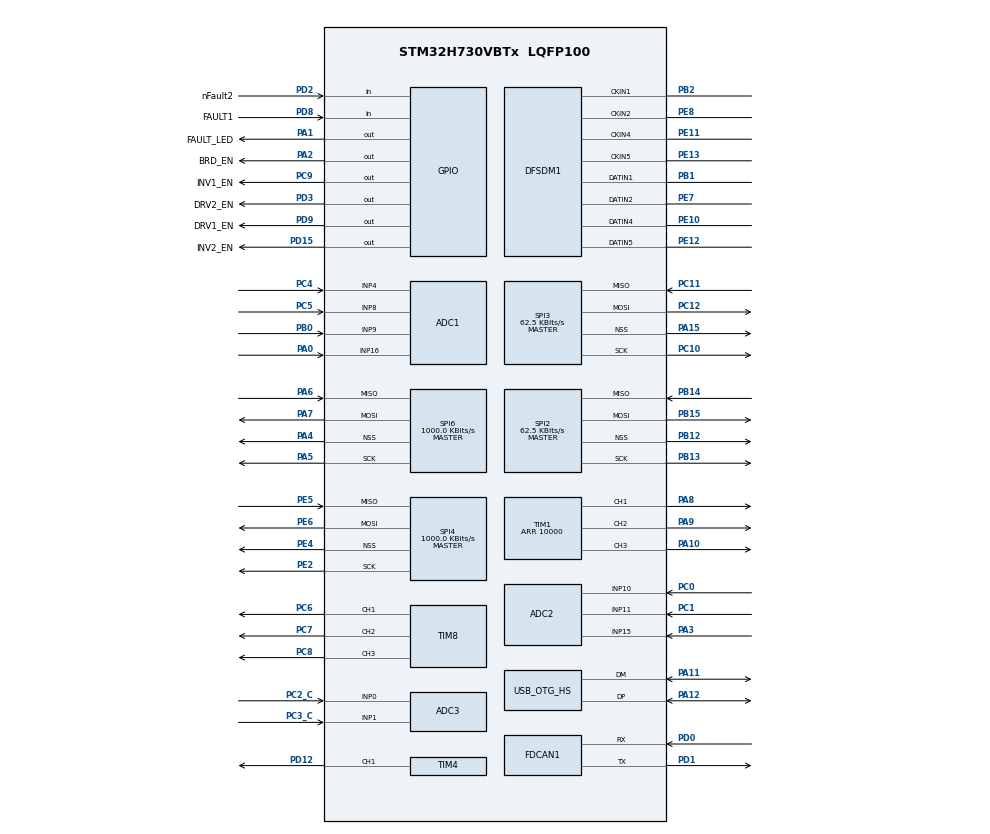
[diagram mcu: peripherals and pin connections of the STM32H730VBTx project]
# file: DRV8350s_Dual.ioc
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ADC1.Channel-10\#ChannelRegularConversion=ADC_CHANNEL_4
ADC1.Channel-11\#ChannelRegularConversion=ADC_CHANNEL_8
ADC1.Channel-12\#ChannelRegularConversion=ADC_CHANNEL_9
ADC1.Channel-13\#ChannelRegularConversion=ADC_CHANNEL_16
ADC1.ClockPrescaler=ADC_CLOCK_ASYNC_DIV6
ADC1.ContinuousConvMode=ENABLE
ADC1.ConversionDataManagement=ADC_CONVERSIONDATA_DR
ADC1.EOCSelection=ADC_EOC_SINGLE_CONV
ADC1.EnableRegularConversion=ENABLE
ADC1.ExternalTrigConv=ADC_SOFTWARE_START
ADC1.NbrOfConversion=4
ADC1.NbrOfConversionFlag=1
ADC1.OffsetNumber-10\#ChannelRegularConversion=ADC_OFFSET_NONE
ADC1.OffsetNumber-11\#ChannelRegularConversion=ADC_OFFSET_NONE
ADC1.OffsetNumber-12\#ChannelRegularConversion=ADC_OFFSET_NONE
ADC1.OffsetNumber-13\#ChannelRegularConversion=ADC_OFFSET_NONE
ADC1.OffsetSignedSaturation-10\#ChannelRegularConversion=DISABLE
ADC1.OffsetSignedSaturation-11\#ChannelRegularConversion=DISABLE
ADC1.OffsetSignedSaturation-12\#ChannelRegularConversion=DISABLE
ADC1.OffsetSignedSaturation-13\#ChannelRegularConversion=DISABLE
ADC1.Overrun=ADC_OVR_DATA_OVERWRITTEN
ADC1.OversamplingMode=ENABLE
ADC1.Rank-10\#ChannelRegularConversion=1
ADC1.Rank-11\#ChannelRegularConversion=2
ADC1.Rank-12\#ChannelRegularConversion=3
ADC1.Rank-13\#ChannelRegularConversion=4
ADC1.Ratio=2
ADC1.RightBitShift=ADC_RIGHTBITSHIFT_NONE
ADC1.SamplingTime-10\#ChannelRegularConversion=ADC_SAMPLETIME_64CYCLES_5
ADC1.SamplingTime-11\#ChannelRegularConversion=ADC_SAMPLETIME_64CYCLES_5
ADC1.SamplingTime-12\#ChannelRegularConversion=ADC_SAMPLETIME_64CYCLES_5
ADC1.SamplingTime-13\#ChannelRegularConversion=ADC_SAMPLETIME_64CYCLES_5
ADC1.master=1
ADC2.Channel-3\#ChannelRegularConversion=ADC_CHANNEL_10
ADC2.Channel-4\#ChannelRegularConversion=ADC_CHANNEL_11
ADC2.Channel-5\#ChannelRegularConversion=ADC_CHANNEL_15
ADC2.ClockPrescaler=ADC_CLOCK_ASYNC_DIV6
ADC2.ContinuousConvMode=DISABLE
ADC2.ConversionDataManagement=ADC_CONVERSIONDATA_DMA_CIRCULAR
ADC2.EOCSelection=ADC_EOC_SINGLE_CONV
ADC2.NbrOfConversion=3
ADC2.NbrOfConversionFlag=1
ADC2.OffsetNumber-3\#ChannelRegularConversion=ADC_OFFSET_NONE
ADC2.OffsetNumber-4\#ChannelRegularConversion=ADC_OFFSET_NONE
ADC2.OffsetNumber-5\#ChannelRegularConversion=ADC_OFFSET_NONE
ADC2.OffsetSignedSaturation-3\#ChannelRegularConversion=DISABLE
ADC2.OffsetSignedSaturation-4\#ChannelRegularConversion=DISABLE
ADC2.OffsetSignedSaturation-5\#ChannelRegularConversion=DISABLE
ADC2.Overrun=ADC_OVR_DATA_OVERWRITTEN
ADC2.Rank-3\#ChannelRegularConversion=1
ADC2.Rank-4\#ChannelRegularConversion=2
ADC2.Rank-5\#ChannelRegularConversion=3
ADC2.SamplingTime-3\#ChannelRegularConversion=ADC_SAMPLETIME_8CYCLES_5
ADC2.SamplingTime-4\#ChannelRegularConversion=ADC_SAMPLETIME_8CYCLES_5
ADC2.SamplingTime-5\#ChannelRegularConversion=ADC_SAMPLETIME_8CYCLES_5
ADC3.Channel-4\#ChannelRegularConversion=ADC_CHANNEL_1
ADC3.ClockPrescaler=ADC_CLOCK_ASYNC_DIV6
ADC3.ContinuousConvMode=ENABLE
ADC3.ConversionDataManagement=ADC_CONVERSIONDATA_DR
ADC3.DMAContinuousRequests=DISABLE
ADC3.EOCSelection=ADC_EOC_SINGLE_CONV
ADC3.NbrOfConversion=1
ADC3.NbrOfConversionFlag=1
ADC3.OffsetNumber-4\#ChannelRegularConversion=ADC_OFFSET_NONE
ADC3.OffsetSaturation-4\#ChannelRegularConversion=DISABLE
ADC3.OffsetSign-4\#ChannelRegularConversion=ADC3_OFFSET_SIGN_NEGATIVE
ADC3.OffsetSignedSaturation-4\#ChannelRegularConversion=DISABLE
ADC3.Overrun=ADC_OVR_DATA_OVERWRITTEN
ADC3.OversamplingMode=ENABLE
ADC3.Rank-4\#ChannelRegularConversion=1
ADC3.Ratio=16
ADC3.RightBitShift=ADC_RIGHTBITSHIFT_5
ADC3.SamplingTime-4\#ChannelRegularConversion=ADC3_SAMPLETIME_92CYCLES_5
CORTEX_M7.CPU_ICache=Enabled
DFSDM1.Filter_regChannel_FIL0=DFSDM_CHANNEL_1
DFSDM1.Filter_regChannel_FIL1=DFSDM_CHANNEL_2
DFSDM1.Filter_regChannel_FIL2=DFSDM_CHANNEL_4
DFSDM1.Filter_regChannel_FIL3=DFSDM_CHANNEL_5
DFSDM1.Fosr_FIL0=32
DFSDM1.Fosr_FIL1=32
DFSDM1.Fosr_FIL2=32
DFSDM1.Fosr_FIL3=32
DFSDM1.SincOrder_FIL0=DFSDM_FILTER_SINC3_ORDER
DFSDM1.SincOrder_FIL1=DFSDM_FILTER_SINC3_ORDER
DFSDM1.SincOrder_FIL2=DFSDM_FILTER_SINC3_ORDER
DFSDM1.SincOrder_FIL3=DFSDM_FILTER_SINC3_ORDER
DFSDM1.Type_spi_CH1=DFSDM_CHANNEL_SPI_RISING
Dma.ADC2.0.Direction=DMA_PERIPH_TO_MEMORY
Dma.ADC2.0.EventEnable=DISABLE
Dma.ADC2.0.FIFOMode=DMA_FIFOMODE_DISABLE
Dma.ADC2.0.Instance=DMA1_Stream1
Dma.ADC2.0.MemDataAlignment=DMA_MDATAALIGN_WORD
Dma.ADC2.0.MemInc=DMA_MINC_ENABLE
Dma.ADC2.0.Mode=DMA_CIRCULAR
Dma.ADC2.0.PeriphDataAlignment=DMA_PDATAALIGN_WORD
Dma.ADC2.0.PeriphInc=DMA_PINC_DISABLE
Dma.ADC2.0.Polarity=HAL_DMAMUX_REQ_GEN_RISING
Dma.ADC2.0.Priority=DMA_PRIORITY_MEDIUM
Dma.ADC2.0.RequestNumber=1
Dma.ADC2.0.SignalID=NONE
Dma.ADC2.0.SyncEnable=DISABLE
Dma.ADC2.0.SyncPolarity=HAL_DMAMUX_SYNC_NO_EVENT
Dma.ADC2.0.SyncRequestNumber=1
Dma.ADC2.0.SyncSignalID=NONE
Dma.Request0=ADC2
Mcu.Family=STM32H7
Mcu.Name=STM32H730VBTx
Mcu.Package=LQFP100
NVIC.ADC3_IRQn=true\:0\:0\:false\:false\:true\:true\:true\:true
NVIC.ADC_IRQn=true\:0\:0\:false\:false\:true\:true\:true\:true
NVIC.DMA1_Stream1_IRQn=true\:0\:0\:false\:false\:true\:false\:true\:true
NVIC.OTG_HS_IRQn=true\:0\:0\:false\:false\:true\:false\:true\:true
NVIC.PriorityGroup=NVIC_PRIORITYGROUP_4
NVIC.TIM2_IRQn=true\:0\:0\:false\:false\:true\:true\:true\:true
PA0.Mode=IN16-Single-Ended
PA0.Signal=ADC1_INP16
PA1.GPIO_Label=FAULT_LED
PA1.Signal=GPIO_Output
PA10.Signal=S_TIM1_CH3
PA11.Mode=Device_Only_FS
PA11.Signal=USB_OTG_HS_DM
PA12.Mode=Device_Only_FS
PA12.Signal=USB_OTG_HS_DP
PA13(JTMS/SWDIO).Mode=Serial_Wire
PA13(JTMS/SWDIO).Signal=DEBUG_JTMS-SWDIO
PA14(JTCK/SWCLK).Mode=Serial_Wire
PA14(JTCK/SWCLK).Signal=DEBUG_JTCK-SWCLK
PA15(JTDI).GPIO_PuPd=GPIO_NOPULL
PA15(JTDI).Mode=NSS_Signal_Hard_Output
PA15(JTDI).Signal=SPI3_NSS
PA2.GPIO_Label=BRD_EN
PA2.Signal=GPIO_Output
PA3.Signal=ADCx_INP15
PA4.Mode=NSS_Signal_Hard_Output
PA4.Signal=SPI6_NSS
PA5.Mode=Full_Duplex_Master
PA5.Signal=SPI6_SCK
PA6.GPIO_PuPd=GPIO_NOPULL
PA6.Mode=Full_Duplex_Master
PA6.Signal=SPI6_MISO
PA7.Mode=Full_Duplex_Master
PA7.Signal=SPI6_MOSI
PA8.Signal=S_TIM1_CH1
PA9.Signal=S_TIM1_CH2
PB0.Signal=ADCx_INP9
PB1.Signal=S_DATAIN1DFSDM1
PB12.GPIO_PuPd=GPIO_NOPULL
PB12.Mode=NSS_Signal_Hard_Output
PB12.Signal=SPI2_NSS
PB13.Mode=Full_Duplex_Master
PB13.Signal=SPI2_SCK
PB14.GPIO_PuPd=GPIO_PULLUP
PB14.Mode=Full_Duplex_Master
PB14.Signal=SPI2_MISO
PB15.GPIO_PuPd=GPIO_NOPULL
PB15.Mode=Full_Duplex_Master
PB15.Signal=SPI2_MOSI
PB2.Signal=S_CKIN1DFSDM1
PC0.Signal=ADCx_INP10
PC1.Signal=ADCx_INP11
PC10.Mode=Full_Duplex_Master
PC10.Signal=SPI3_SCK
PC11.GPIO_PuPd=GPIO_PULLUP
PC11.Mode=Full_Duplex_Master
PC11.Signal=SPI3_MISO
PC12.Mode=Full_Duplex_Master
PC12.Signal=SPI3_MOSI
PC2_C.Mode=IN0-Single-Ended
PC2_C.Signal=ADC3_INP0
PC3_C.Mode=IN1-Single-Ended
PC3_C.Signal=ADC3_INP1
PC4.Signal=ADCx_INP4
PC5.Signal=ADCx_INP8
PC6.Signal=S_TIM8_CH1
PC7.Signal=S_TIM8_CH2
PC8.Signal=S_TIM8_CH3
PC9.GPIO_Label=INV1_EN
PC9.Signal=GPIO_Output
PD0.Mode=FDCAN_Activate
PD0.Signal=FDCAN1_RX
PD1.Mode=FDCAN_Activate
PD1.Signal=FDCAN1_TX
PD12.Signal=S_TIM4_CH1
PD15.GPIO_Label=INV2_EN
PD15.Signal=GPIO_Output
PD2.GPIO_Label=nFault2
PD2.Signal=GPIO_Input
PD3.GPIO_Label=DRV2_EN
PD3.Signal=GPIO_Output
PD8.GPIO_Label=FAULT1
PD8.Signal=GPIO_Input
PD9.GPIO_Label=DRV1_EN
PD9.Signal=GPIO_Output
PE10.Signal=S_DATAIN4DFSDM1
PE11.Signal=S_CKIN4DFSDM1
PE12.Signal=S_DATAIN5DFSDM1
PE13.Signal=S_CKIN5DFSDM1
PE2.Mode=Full_Duplex_Master
PE2.Signal=SPI4_SCK
PE4.GPIO_PuPd=GPIO_NOPULL
PE4.Mode=NSS_Signal_Hard_Output
PE4.Signal=SPI4_NSS
PE5.Mode=Full_Duplex_Master
PE5.Signal=SPI4_MISO
PE6.Mode=Full_Duplex_Master
PE6.Signal=SPI4_MOSI
PE7.Signal=S_DATAIN2DFSDM1
PE8.Signal=S_CKIN2DFSDM1
PH0-OSC_IN.Mode=HSE-External-Clock-Source
PH0-OSC_IN.Signal=RCC_OSC_IN
ProjectManager.HeapSize=0x200
ProjectManager.StackSize=0x400
ProjectManager.TargetToolchain=STM32CubeIDE
RCC.ADCCLockSelection=RCC_ADCCLKSOURCE_CLKP
RCC.ADCFreq_Value=4000000
RCC.APB1Freq_Value=137499975
RCC.APB2Freq_Value=137499975
RCC.APB3Freq_Value=137499975
RCC.APB4Freq_Value=137499975
RCC.CKPERSourceSelection=RCC_CLKPSOURCE_CSI
RCC.CortexFreq_Value=549999900
RCC.D1PPRE=RCC_APB3_DIV2
RCC.D2PPRE1=RCC_APB1_DIV2
RCC.D2PPRE2=RCC_APB2_DIV2
RCC.D3PPRE=RCC_APB4_DIV2
RCC.DIVM1=3
RCC.DIVM2=4
RCC.DIVM3=1
RCC.DIVN1=74
RCC.DIVN2=17
RCC.DIVN3=6
RCC.DIVP1=1
RCC.DIVP2=1
RCC.DIVP3=1
RCC.DIVQ1=10
RCC.DIVQ2=1
RCC.DIVQ3=1
RCC.DIVR1=10
RCC.DIVR3=1
RCC.FDCANCLockSelection=RCC_FDCANCLKSOURCE_HSE
RCC.HCLKFreq_Value=274999950
RCC.HPRE=RCC_HCLK_DIV2
RCC.HSE_Timout=1000
RCC.HSE_VALUE=22118400
RCC.HSICalibrationValue=8
RCC.HSIDiv=RCC_PLLSAIDIVR_8
RCC.PLL2FRACN=4699
RCC.PLL3FRACN=0
RCC.PLLFRACN=4903
RCC.PLLSourceVirtual=RCC_PLLSOURCE_HSE
RCC.SPI123CLockSelection=RCC_SPI123CLKSOURCE_CLKP
RCC.SPI6CLockSelection=RCC_SPI6CLKSOURCE_CSI
RCC.SYSCLKFreq_VALUE=549999900
RCC.SYSCLKSource=RCC_SYSCLKSOURCE_PLLCLK
RCC.Spi45ClockSelection=RCC_SPI45CLKSOURCE_CSI
RCC.SupplySource=PWR_LDO_SUPPLY
RCC.USBCLockSelection=RCC_USBCLKSOURCE_HSI48
RCC.USBFreq_Value=48000000
SH.ADCx_INP10.0=ADC2_INP10,IN10-Single-Ended
SH.ADCx_INP11.0=ADC2_INP11,IN11-Single-Ended
SH.ADCx_INP15.0=ADC2_INP15,IN15-Single-Ended
SH.ADCx_INP4.0=ADC1_INP4,IN4-Single-Ended
SH.ADCx_INP8.0=ADC1_INP8,IN8-Single-Ended
SH.ADCx_INP9.0=ADC1_INP9,IN9-Single-Ended
SH.S_CKIN1DFSDM1.0=DFSDM1_CKIN1,PDM_SPI_input_from_ch1_and_external_clock
SH.S_CKIN2DFSDM1.0=DFSDM1_CKIN2,PDM_SPI_input_from_ch2_and_external_clock
SH.S_CKIN4DFSDM1.0=DFSDM1_CKIN4,PDM_SPI_input_from_ch4_and_external_clock
SH.S_CKIN5DFSDM1.0=DFSDM1_CKIN5,PDM_SPI_input_from_ch5_and_external_clock
SH.S_DATAIN1DFSDM1.0=DFSDM1_DATIN1,PDM_SPI_input_from_ch1_and_external_clock
SH.S_DATAIN2DFSDM1.0=DFSDM1_DATIN2,PDM_SPI_input_from_ch2_and_external_clock
SH.S_DATAIN4DFSDM1.0=DFSDM1_DATIN4,PDM_SPI_input_from_ch4_and_external_clock
SH.S_DATAIN5DFSDM1.0=DFSDM1_DATIN5,PDM_SPI_input_from_ch5_and_external_clock
SH.S_TIM1_CH1.0=TIM1_CH1,PWM Generation1 CH1
SH.S_TIM1_CH2.0=TIM1_CH2,PWM Generation2 CH2
SH.S_TIM1_CH3.0=TIM1_CH3,PWM Generation3 CH3
SH.S_TIM4_CH1.0=TIM4_CH1,PWM Generation1 CH1
SH.S_TIM8_CH1.0=TIM8_CH1,PWM Generation1 CH1
SH.S_TIM8_CH2.0=TIM8_CH2,PWM Generation2 CH2
SH.S_TIM8_CH3.0=TIM8_CH3,Output Compare3 CH3
SPI2.BaudRatePrescaler=SPI_BAUDRATEPRESCALER_64
SPI2.CLKPhase=SPI_PHASE_2EDGE
SPI2.CalculateBaudRate=62.5 KBits/s
SPI2.DataSize=SPI_DATASIZE_16BIT
SPI2.Direction=SPI_DIRECTION_2LINES
SPI2.MasterKeepIOState=SPI_MASTER_KEEP_IO_STATE_ENABLE
SPI2.Mode=SPI_MODE_MASTER
SPI2.NSSPMode=SPI_NSS_PULSE_DISABLE
SPI2.NSSPolarity=SPI_NSS_POLARITY_LOW
SPI2.VirtualNSS=VM_NSSHARD
SPI2.VirtualType=VM_MASTER
SPI3.BaudRatePrescaler=SPI_BAUDRATEPRESCALER_64
SPI3.CLKPhase=SPI_PHASE_2EDGE
SPI3.CalculateBaudRate=62.5 KBits/s
SPI3.DataSize=SPI_DATASIZE_16BIT
SPI3.Direction=SPI_DIRECTION_2LINES
SPI3.MasterKeepIOState=SPI_MASTER_KEEP_IO_STATE_ENABLE
SPI3.Mode=SPI_MODE_MASTER
SPI3.NSSPMode=SPI_NSS_PULSE_DISABLE
SPI3.NSSPolarity=SPI_NSS_POLARITY_LOW
SPI3.VirtualNSS=VM_NSSHARD
SPI3.VirtualType=VM_MASTER
SPI4.BaudRatePrescaler=SPI_BAUDRATEPRESCALER_4
SPI4.CLKPhase=SPI_PHASE_2EDGE
SPI4.CLKPolarity=SPI_POLARITY_HIGH
SPI4.CalculateBaudRate=1000.0 KBits/s
SPI4.DataSize=SPI_DATASIZE_16BIT
SPI4.Direction=SPI_DIRECTION_2LINES
SPI4.IOSwap=SPI_IO_SWAP_DISABLE
SPI4.MasterKeepIOState=SPI_MASTER_KEEP_IO_STATE_ENABLE
SPI4.Mode=SPI_MODE_MASTER
SPI4.NSSPMode=SPI_NSS_PULSE_DISABLE
SPI4.NSSPolarity=SPI_NSS_POLARITY_HIGH
SPI4.VirtualNSS=VM_NSSHARD
SPI4.VirtualType=VM_MASTER
SPI6.BaudRatePrescaler=SPI_BAUDRATEPRESCALER_4
SPI6.CLKPhase=SPI_PHASE_2EDGE
SPI6.CLKPolarity=SPI_POLARITY_HIGH
SPI6.CalculateBaudRate=1000.0 KBits/s
SPI6.DataSize=SPI_DATASIZE_16BIT
SPI6.Direction=SPI_DIRECTION_2LINES
SPI6.Mode=SPI_MODE_MASTER
SPI6.NSSPMode=SPI_NSS_PULSE_DISABLE
SPI6.NSSPolarity=SPI_NSS_POLARITY_HIGH
SPI6.VirtualNSS=VM_NSSHARD
SPI6.VirtualType=VM_MASTER
TIM1.Channel-PWM\ Generation1\ CH1=TIM_CHANNEL_1
TIM1.Channel-PWM\ Generation2\ CH2=TIM_CHANNEL_2
TIM1.Channel-PWM\ Generation3\ CH3=TIM_CHANNEL_3
TIM1.Period=10000
TIM2.Period=655350
TIM2.TIM_MasterOutputTrigger=TIM_TRGO_RESET
TIM4.Channel-PWM\ Generation1\ CH1=TIM_CHANNEL_1
TIM4.Period=20000
TIM4.Prescaler=27500
TIM8.Channel-Output\ Compare3\ CH3=TIM_CHANNEL_3
TIM8.Channel-PWM\ Generation1\ CH1=TIM_CHANNEL_1
TIM8.Channel-PWM\ Generation2\ CH2=TIM_CHANNEL_2
USB_DEVICE.CLASS_NAME_HS=CDC
USB_DEVICE.USBD_DEBUG_LEVEL=3
USB_DEVICE.VirtualMode=Cdc
USB_DEVICE.VirtualModeHS=Cdc_HS
USB_OTG_HS.VirtualMode-Device_Only_FS=Device_Only_FS
VP_CORDIC_VS_CORDIC.Mode=CORDIC_Activate
VP_FMAC_VS_FMAC.Mode=FMAC_Activate
VP_TIM1_VS_ClockSourceINT.Mode=Internal
VP_TIM2_VS_ClockSourceINT.Mode=Internal
VP_TIM4_VS_ClockSourceINT.Mode=Internal
VP_TIM8_VS_ClockSourceINT.Mode=Internal
VP_USB_DEVICE_VS_USB_DEVICE_CDC_HS.Mode=CDC_HS
VREF+.Mode=InternalMode
VREF+.Signal=VREFBUF_OUT
VREFBUF.TrimmingMode=__NULL
VREFBUF.VoltageScaling=SYSCFG_VREFBUF_VOLTAGE_SCALE1
board=custom

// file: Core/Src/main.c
/* USER CODE BEGIN Header */
/**
  ******************************************************************************
  * @file           : main.c
  * @brief          : Main program body
  ******************************************************************************
  * @attention
  *
  * <h2><center>&copy; Copyright (c) 2021 STMicroelectronics.
  * All rights reserved.</center></h2>
  *
  * This software component is licensed by ST under BSD 3-Clause license,
  * the "License"; You may not use this file except in compliance with the
  * License. You may obtain a copy of the License at:
  *                        opensource.org/licenses/BSD-3-Clause
  *
  ******************************************************************************
  */
/* USER CODE END Header */
#include "main.h"
#include "usb_device.h"
/* USER CODE BEGIN Includes */
#include "drv8350s.h"
#include "FOC.h"
#include "PI_loop.h"
#include "pos_offset_cal.h"
#include "controller_cfg.h"
/* USER CODE END Includes */

 ADC_HandleTypeDef hadc1;
ADC_HandleTypeDef hadc2;
ADC_HandleTypeDef hadc3;
DMA_HandleTypeDef hdma_adc2;

CORDIC_HandleTypeDef hcordic;

DFSDM_Filter_HandleTypeDef hdfsdm1_filter0;
DFSDM_Filter_HandleTypeDef hdfsdm1_filter1;
DFSDM_Filter_HandleTypeDef hdfsdm1_filter2;
DFSDM_Filter_HandleTypeDef hdfsdm1_filter3;
DFSDM_Channel_HandleTypeDef hdfsdm1_channel1;
DFSDM_Channel_HandleTypeDef hdfsdm1_channel2;
DFSDM_Channel_HandleTypeDef hdfsdm1_channel4;
DFSDM_Channel_HandleTypeDef hdfsdm1_channel5;

FDCAN_HandleTypeDef hfdcan1;

FMAC_HandleTypeDef hfmac;

SPI_HandleTypeDef hspi2;
SPI_HandleTypeDef hspi3;
SPI_HandleTypeDef hspi4;
SPI_HandleTypeDef hspi6;

TIM_HandleTypeDef htim1;
TIM_HandleTypeDef htim2;
TIM_HandleTypeDef htim4;
TIM_HandleTypeDef htim8;

/* USER CODE BEGIN PV */
	//uint32_t __attribute__((section("RAM_D1"))) adc1[4]={0} ;
uint32_t adc1[4]={0} ;
uint32_t adc2[3]={0};
uint32_t adc3[2]={0};
int request_pos = 0xffff;
float data2angle = 360.0 / 4096;
int volatile position=0;
int volatile position_2=0;
float angle=0,angle_2=0;
float foc_angle=0,speed=0;
int adc_count=0;
/* USER CODE END PV */

void SystemClock_Config(void);
void PeriphCommonClock_Config(void);
static void MX_GPIO_Init(void);
static void MX_ADC1_Init(void);
static void MX_ADC2_Init(void);
static void MX_CORDIC_Init(void);
static void MX_DFSDM1_Init(void);
static void MX_FDCAN1_Init(void);
static void MX_FMAC_Init(void);
static void MX_SPI2_Init(void);
static void MX_SPI3_Init(void);
static void MX_SPI4_Init(void);
static void MX_SPI6_Init(void);
static void MX_TIM1_Init(void);
static void MX_TIM8_Init(void);
static void MX_DMA_Init(void);
static void MX_TIM2_Init(void);
static void MX_ADC3_Init(void);
static void MX_TIM4_Init(void);

/* USER CODE BEGIN 0 */
//	uint32_t adc1[4];

/* USER CODE END 0 */

int main(void)
{

  /* Enable I-Cache---------------------------------------------------------*/
  SCB_EnableICache();

  /* MCU Configuration--------------------------------------------------------*/

  /* Reset of all peripherals, Initializes the Flash interface and the Systick. */
  HAL_Init();

  /* Configure the system clock */
  SystemClock_Config();

/* Configure the peripherals common clocks */
  PeriphCommonClock_Config();

  /* USER CODE BEGIN SysInit */
//  volatile uint32_t adc1;

  /* USER CODE END SysInit */

  /* Initialize all configured peripherals */
  MX_GPIO_Init();
  MX_ADC1_Init();
  MX_ADC2_Init();
  MX_CORDIC_Init();
  MX_DFSDM1_Init();
  MX_FDCAN1_Init();
  MX_FMAC_Init();
  MX_SPI2_Init();
  MX_SPI3_Init();
  MX_SPI4_Init();
  MX_SPI6_Init();
  MX_TIM1_Init();
  MX_TIM8_Init();
  MX_DMA_Init();
  MX_USB_DEVICE_Init();
  MX_TIM2_Init();
  MX_ADC3_Init();
  MX_TIM4_Init();
  /* USER CODE BEGIN 2 */
  HAL_GPIO_WritePin(FAULT_LED_GPIO_Port, FAULT_LED_Pin, GPIO_PIN_SET);
  HAL_GPIO_WritePin(BRD_EN_GPIO_Port, BRD_EN_Pin, GPIO_PIN_SET);
  HAL_Delay (100);
  if(HAL_DFSDM_FilterRegularStart(&hdfsdm1_filter0) != HAL_OK){
	  Error_Handler();
  }
  if(HAL_DFSDM_FilterRegularStart(&hdfsdm1_filter1) != HAL_OK){
	  Error_Handler();
  }
  if(HAL_DFSDM_FilterRegularStart(&hdfsdm1_filter2) != HAL_OK){
	  Error_Handler();
  }
  if(HAL_DFSDM_FilterRegularStart(&hdfsdm1_filter3) != HAL_OK){
	  Error_Handler();
  }
  HAL_TIM_Base_Start_IT(&htim1);
  HAL_TIM_PWM_Start(&htim1, TIM_CHANNEL_1);
  HAL_TIM_PWM_Start(&htim1, TIM_CHANNEL_2);
  HAL_TIM_PWM_Start(&htim1, TIM_CHANNEL_3);
  HAL_TIM_PWM_Start(&htim1, TIM_CHANNEL_4);
  HAL_TIM_Base_Start_IT(&htim2);
  HAL_TIM_Base_Start(&htim4);
//  HAL_TIM_Base_Start_IT(&htim8);
  TIM4->CCER = 0b0000010101010101;
  TIM4->CCR1 = 10000;
  TIM1->CCER = 0b0000010101010101;
  TIM1->CCR1 = 0;
  TIM1->CCR2 = 0;
  TIM1->CCR3 = 0;
  TIM1->CCR4 = 0;
  uint8_t data[] = "Hello World from USB CDC123\n";
  float current_C1 = 0, current_A1 = 0, current_C2 = 0, current_A2 = 0;
  float prev_angle,angle_sum;
  uint8_t result=0;
  uint32_t channel1 = 0, channel2 = 0, channel4 = 0, channel5 = 0;
  uint16_t length = strlen(data);
  uint16_t regs_data[6] = {0};
  /*
  if(HAL_ADC_Start_DMA(&hadc1, adc1, 4) != HAL_OK){
  	  Error_Handler();
  }
  */
  //HAL_ADC_Start_DMA(&hadc2, adc2, 3);
 //HAL_ADC_Start_DMA(&hadc3, adc3, 1);
  HAL_ADC_Start(&hadc3);
  // Setup DRV
  HAL_GPIO_WritePin(DRV1_EN_GPIO_Port, DRV1_EN_Pin, GPIO_PIN_SET);
  HAL_GPIO_WritePin(DRV2_EN_GPIO_Port, DRV2_EN_Pin, GPIO_PIN_SET);
  HAL_GPIO_WritePin(GPIOA, FAULT_LED_Pin|BRD_EN_Pin, GPIO_PIN_SET);
  HAL_GPIO_WritePin(INV1_EN_GPIO_Port, INV1_EN_Pin, GPIO_PIN_SET);
  HAL_SPI_TransmitReceive(&hspi6, (uint8_t*) &request_pos, (uint8_t*) &position, 1, 100);

  //spi setup
  set_driver_ctrl_reg(&hspi2, SHUTDOWN_ALL_BRIDGES, UVLO_EN, GATE_DRV_FAULT_EN, OTW_REPORT_EN, PWM_3X, SYNC_RECT, CW, COAST_DIS, NO_TPS);
  set_hs_driver_reg(&hspi2, UNLOCK_REGS, IDRIVEP_1000MA, IDRIVEN_1200MA);
  set_ls_driver_ctrl_reg(&hspi2, RETRY_ONLY, PK_CUR_2000NS, IDRIVEP_1000MA, IDRIVEN_1200MA);
  set_ocp_ctrl_reg(&hspi2, RETRY_8MS, DEAD_TIME_200NS, OC_LATCHED, OCP_DEG_8US, VDS_LVL_1_0V);
  HAL_Delay(10);
  clear_flt(&hspi2);
  HAL_Delay(10);
  float ma732_offset_pre = read_offset(&hspi4);
  MA732_ROT_DIR ma732_dir_pre = read_rot_dir(&hspi4);
  reset_offset_and_dir(&hspi4);
  float ma732_offset_post_reset = read_offset(&hspi4);
  MA732_ROT_DIR ma732_dir_post_reset = read_rot_dir(&hspi4);
  SENSOR_OFFSET_E mot_offset_1 = get_pos_offset(TIM1, &hspi4);
  //SENSOR_OFFSET_E mot_offset_2 = get_pos_offset(TIM8, &hspi6);
  //set_offset(&hspi4, mot_offset_1.offset);
  set_dir(&hspi4,mot_offset_1.direction);
  HAL_Delay(10);
  SENSOR_OFFSET_E mot_offset_1_rnd2 = get_pos_offset(TIM1, &hspi4);
  set_offset(&hspi4, mot_offset_1_rnd2.offset);
  float ma732_offset_after = read_offset(&hspi4);
  MA732_ROT_DIR ma732_dir_after = read_rot_dir(&hspi4);
  int32_t tim_period = TIM1->ARR;
  int Va, Vb, Vc, min_val;
  /* USER CODE END 2 */

  /* Infinite loop */
  /* USER CODE BEGIN WHILE */
  while (1)
  {
	  read_all_regs(&hspi2, regs_data);
	  current_C1 = HAL_DFSDM_FilterGetRegularValue(&hdfsdm1_filter0, &channel1) * CURRENT_A_SCALER;
	  current_A1 = HAL_DFSDM_FilterGetRegularValue(&hdfsdm1_filter1, &channel2) * CURRENT_A_SCALER;
	  current_C2 = HAL_DFSDM_FilterGetRegularValue(&hdfsdm1_filter2, &channel4) * CURRENT_A_SCALER;
	  current_A2 = HAL_DFSDM_FilterGetRegularValue(&hdfsdm1_filter3, &channel5) * CURRENT_A_SCALER;
	  int dc_bus_fxpt = HAL_ADC_GetValue(&hadc3);
	  float dc_bus = dc_bus_fxpt*0.028998778998779f;
	  HAL_SPI_TransmitReceive(&hspi6, (uint8_t*) &request_pos, (uint8_t*) &position_2, 1, 100);
	  HAL_SPI_TransmitReceive(&hspi4, (uint8_t*) &request_pos, (uint8_t*) &position, 1, 100);
	  int position_temp = position >> 4;
	  int position_temp_2 = position_2 >> 4;
	  angle = data2angle * position_temp;
	  angle_2 = data2angle * position_temp_2;
	  //speed cal
	  float diff_angle = angle - prev_angle;
	  if(diff_angle > 180){
		  diff_angle -= 360;
	  }
	  else if(diff_angle < -180){
		diff_angle += 360;
	  }
	  angle_sum += diff_angle;
	  prev_angle = angle;
	  uint16_t e_position= ((position_temp * mot_offset_1.pole_pairs))%1024;
	  inv_parkclark(&Va, &Vb, &Vc, e_position, 400, 0);
	  min_val = find_min_voltage(Va, Vb, Vc);
	  Va -= min_val;
	  Vb -= min_val;
	  Vc -= min_val;
	  TIM1->CCR1 = (Va*tim_period)/DC_BUS_V;
	  TIM1->CCR2 = (Vb*tim_period)/DC_BUS_V;
	  TIM1->CCR3 = (Vc*tim_period)/DC_BUS_V;

	  //	  uint32_t *adc1_add = adc1;
	  HAL_Delay (1);
    /* USER CODE END WHILE */

  }
}

void SystemClock_Config(void)
{
  RCC_OscInitTypeDef RCC_OscInitStruct = {0};
  RCC_ClkInitTypeDef RCC_ClkInitStruct = {0};

  /** Supply configuration update enable
  */
  HAL_PWREx_ConfigSupply(PWR_LDO_SUPPLY);

  /** Configure the main internal regulator output voltage
  */
  __HAL_PWR_VOLTAGESCALING_CONFIG(PWR_REGULATOR_VOLTAGE_SCALE0);

  while(!__HAL_PWR_GET_FLAG(PWR_FLAG_VOSRDY)) {}

  /** Initializes the RCC Oscillators according to the specified parameters
  * in the RCC_OscInitTypeDef structure.
  */
  RCC_OscInitStruct.OscillatorType = RCC_OSCILLATORTYPE_HSI48|RCC_OSCILLATORTYPE_CSI
                              |RCC_OSCILLATORTYPE_HSE;
  RCC_OscInitStruct.HSEState = RCC_HSE_BYPASS;
  RCC_OscInitStruct.HSI48State = RCC_HSI48_ON;
  RCC_OscInitStruct.CSIState = RCC_CSI_ON;
  RCC_OscInitStruct.CSICalibrationValue = 16;
  RCC_OscInitStruct.PLL.PLLState = RCC_PLL_ON;
  RCC_OscInitStruct.PLL.PLLSource = RCC_PLLSOURCE_HSE;
  RCC_OscInitStruct.PLL.PLLM = 3;
  RCC_OscInitStruct.PLL.PLLN = 74;
  RCC_OscInitStruct.PLL.PLLP = 1;
  RCC_OscInitStruct.PLL.PLLQ = 10;
  RCC_OscInitStruct.PLL.PLLR = 10;
  RCC_OscInitStruct.PLL.PLLRGE = RCC_PLL1VCIRANGE_2;
  RCC_OscInitStruct.PLL.PLLVCOSEL = RCC_PLL1VCOWIDE;
  RCC_OscInitStruct.PLL.PLLFRACN = 4903;
  if (HAL_RCC_OscConfig(&RCC_OscInitStruct) != HAL_OK)
  {
    Error_Handler();
  }

  /** Initializes the CPU, AHB and APB buses clocks
  */
  RCC_ClkInitStruct.ClockType = RCC_CLOCKTYPE_HCLK|RCC_CLOCKTYPE_SYSCLK
                              |RCC_CLOCKTYPE_PCLK1|RCC_CLOCKTYPE_PCLK2
                              |RCC_CLOCKTYPE_D3PCLK1|RCC_CLOCKTYPE_D1PCLK1;
  RCC_ClkInitStruct.SYSCLKSource = RCC_SYSCLKSOURCE_PLLCLK;
  RCC_ClkInitStruct.SYSCLKDivider = RCC_SYSCLK_DIV1;
  RCC_ClkInitStruct.AHBCLKDivider = RCC_HCLK_DIV2;
  RCC_ClkInitStruct.APB3CLKDivider = RCC_APB3_DIV2;
  RCC_ClkInitStruct.APB1CLKDivider = RCC_APB1_DIV2;
  RCC_ClkInitStruct.APB2CLKDivider = RCC_APB2_DIV2;
  RCC_ClkInitStruct.APB4CLKDivider = RCC_APB4_DIV2;

  if (HAL_RCC_ClockConfig(&RCC_ClkInitStruct, FLASH_LATENCY_3) != HAL_OK)
  {
    Error_Handler();
  }
}

void PeriphCommonClock_Config(void)
{
  RCC_PeriphCLKInitTypeDef PeriphClkInitStruct = {0};

  /** Initializes the peripherals clock
  */
  PeriphClkInitStruct.PeriphClockSelection = RCC_PERIPHCLK_CKPER;
  PeriphClkInitStruct.CkperClockSelection = RCC_CLKPSOURCE_CSI;
  if (HAL_RCCEx_PeriphCLKConfig(&PeriphClkInitStruct) != HAL_OK)
  {
    Error_Handler();
  }
}

static void MX_ADC1_Init(void)
{

  ADC_MultiModeTypeDef multimode = {0};
  ADC_ChannelConfTypeDef sConfig = {0};

  /** Common config
  */
  hadc1.Instance = ADC1;
  hadc1.Init.ClockPrescaler = ADC_CLOCK_ASYNC_DIV6;
  hadc1.Init.Resolution = ADC_RESOLUTION_16B;
  hadc1.Init.ScanConvMode = ADC_SCAN_ENABLE;
  hadc1.Init.EOCSelection = ADC_EOC_SINGLE_CONV;
  hadc1.Init.LowPowerAutoWait = DISABLE;
  hadc1.Init.ContinuousConvMode = ENABLE;
  hadc1.Init.NbrOfConversion = 4;
  hadc1.Init.DiscontinuousConvMode = DISABLE;
  hadc1.Init.ExternalTrigConv = ADC_SOFTWARE_START;
  hadc1.Init.ExternalTrigConvEdge = ADC_EXTERNALTRIGCONVEDGE_NONE;
  hadc1.Init.ConversionDataManagement = ADC_CONVERSIONDATA_DR;
  hadc1.Init.Overrun = ADC_OVR_DATA_OVERWRITTEN;
  hadc1.Init.LeftBitShift = ADC_LEFTBITSHIFT_NONE;
  hadc1.Init.OversamplingMode = ENABLE;
  hadc1.Init.Oversampling.Ratio = 2;
  hadc1.Init.Oversampling.RightBitShift = ADC_RIGHTBITSHIFT_NONE;
  hadc1.Init.Oversampling.TriggeredMode = ADC_TRIGGEREDMODE_SINGLE_TRIGGER;
  hadc1.Init.Oversampling.OversamplingStopReset = ADC_REGOVERSAMPLING_CONTINUED_MODE;
  if (HAL_ADC_Init(&hadc1) != HAL_OK)
  {
    Error_Handler();
  }

  /** Configure the ADC multi-mode
  */
  multimode.Mode = ADC_MODE_INDEPENDENT;
  if (HAL_ADCEx_MultiModeConfigChannel(&hadc1, &multimode) != HAL_OK)
  {
    Error_Handler();
  }

  /** Configure Regular Channel
  */
  sConfig.Channel = ADC_CHANNEL_4;
  sConfig.Rank = ADC_REGULAR_RANK_1;
  sConfig.SamplingTime = ADC_SAMPLETIME_64CYCLES_5;
  sConfig.SingleDiff = ADC_SINGLE_ENDED;
  sConfig.OffsetNumber = ADC_OFFSET_NONE;
  sConfig.Offset = 0;
  sConfig.OffsetSignedSaturation = DISABLE;
  if (HAL_ADC_ConfigChannel(&hadc1, &sConfig) != HAL_OK)
  {
    Error_Handler();
  }

  /** Configure Regular Channel
  */
  sConfig.Channel = ADC_CHANNEL_8;
  sConfig.Rank = ADC_REGULAR_RANK_2;
  if (HAL_ADC_ConfigChannel(&hadc1, &sConfig) != HAL_OK)
  {
    Error_Handler();
  }

  /** Configure Regular Channel
  */
  sConfig.Channel = ADC_CHANNEL_9;
  sConfig.Rank = ADC_REGULAR_RANK_3;
  if (HAL_ADC_ConfigChannel(&hadc1, &sConfig) != HAL_OK)
  {
    Error_Handler();
  }

  /** Configure Regular Channel
  */
  sConfig.Channel = ADC_CHANNEL_16;
  sConfig.Rank = ADC_REGULAR_RANK_4;
  if (HAL_ADC_ConfigChannel(&hadc1, &sConfig) != HAL_OK)
  {
    Error_Handler();
  }

}

static void MX_ADC2_Init(void)
{

  ADC_ChannelConfTypeDef sConfig = {0};

  /** Common config
  */
  hadc2.Instance = ADC2;
  hadc2.Init.ClockPrescaler = ADC_CLOCK_ASYNC_DIV6;
  hadc2.Init.Resolution = ADC_RESOLUTION_16B;
  hadc2.Init.ScanConvMode = ADC_SCAN_ENABLE;
  hadc2.Init.EOCSelection = ADC_EOC_SINGLE_CONV;
  hadc2.Init.LowPowerAutoWait = DISABLE;
  hadc2.Init.ContinuousConvMode = DISABLE;
  hadc2.Init.NbrOfConversion = 3;
  hadc2.Init.DiscontinuousConvMode = DISABLE;
  hadc2.Init.ExternalTrigConv = ADC_SOFTWARE_START;
  hadc2.Init.ExternalTrigConvEdge = ADC_EXTERNALTRIGCONVEDGE_NONE;
  hadc2.Init.ConversionDataManagement = ADC_CONVERSIONDATA_DMA_CIRCULAR;
  hadc2.Init.Overrun = ADC_OVR_DATA_OVERWRITTEN;
  hadc2.Init.LeftBitShift = ADC_LEFTBITSHIFT_NONE;
  hadc2.Init.OversamplingMode = DISABLE;
  if (HAL_ADC_Init(&hadc2) != HAL_OK)
  {
    Error_Handler();
  }

  /** Configure Regular Channel
  */
  sConfig.Channel = ADC_CHANNEL_10;
  sConfig.Rank = ADC_REGULAR_RANK_1;
  sConfig.SamplingTime = ADC_SAMPLETIME_8CYCLES_5;
  sConfig.SingleDiff = ADC_SINGLE_ENDED;
  sConfig.OffsetNumber = ADC_OFFSET_NONE;
  sConfig.Offset = 0;
  sConfig.OffsetSignedSaturation = DISABLE;
  if (HAL_ADC_ConfigChannel(&hadc2, &sConfig) != HAL_OK)
  {
    Error_Handler();
  }

  /** Configure Regular Channel
  */
  sConfig.Channel = ADC_CHANNEL_11;
  sConfig.Rank = ADC_REGULAR_RANK_2;
  if (HAL_ADC_ConfigChannel(&hadc2, &sConfig) != HAL_OK)
  {
    Error_Handler();
  }

  /** Configure Regular Channel
  */
  sConfig.Channel = ADC_CHANNEL_15;
  sConfig.Rank = ADC_REGULAR_RANK_3;
  if (HAL_ADC_ConfigChannel(&hadc2, &sConfig) != HAL_OK)
  {
    Error_Handler();
  }

}

static void MX_ADC3_Init(void)
{

  ADC_ChannelConfTypeDef sConfig = {0};

  /** Common config
  */
  hadc3.Instance = ADC3;
  hadc3.Init.ClockPrescaler = ADC_CLOCK_ASYNC_DIV1;
  hadc3.Init.Resolution = ADC_RESOLUTION_12B;
  hadc3.Init.DataAlign = ADC3_DATAALIGN_RIGHT;
  hadc3.Init.ScanConvMode = ADC_SCAN_DISABLE;
  hadc3.Init.EOCSelection = ADC_EOC_SINGLE_CONV;
  hadc3.Init.LowPowerAutoWait = DISABLE;
  hadc3.Init.ContinuousConvMode = ENABLE;
  hadc3.Init.NbrOfConversion = 1;
  hadc3.Init.DiscontinuousConvMode = DISABLE;
  hadc3.Init.ExternalTrigConv = ADC_SOFTWARE_START;
  hadc3.Init.ExternalTrigConvEdge = ADC_EXTERNALTRIGCONVEDGE_NONE;
  hadc3.Init.DMAContinuousRequests = DISABLE;
  hadc3.Init.SamplingMode = ADC_SAMPLING_MODE_NORMAL;
  hadc3.Init.ConversionDataManagement = ADC_CONVERSIONDATA_DR;
  hadc3.Init.Overrun = ADC_OVR_DATA_OVERWRITTEN;
  hadc3.Init.LeftBitShift = ADC_LEFTBITSHIFT_NONE;
  hadc3.Init.OversamplingMode = ENABLE;
  hadc3.Init.Oversampling.Ratio = 16;
  hadc3.Init.Oversampling.RightBitShift = ADC_RIGHTBITSHIFT_5;
  hadc3.Init.Oversampling.TriggeredMode = ADC_TRIGGEREDMODE_SINGLE_TRIGGER;
  hadc3.Init.Oversampling.OversamplingStopReset = ADC_REGOVERSAMPLING_CONTINUED_MODE;
  if (HAL_ADC_Init(&hadc3) != HAL_OK)
  {
    Error_Handler();
  }

  /** Configure Regular Channel
  */
  sConfig.Channel = ADC_CHANNEL_1;
  sConfig.Rank = ADC_REGULAR_RANK_1;
  sConfig.SamplingTime = ADC3_SAMPLETIME_92CYCLES_5;
  sConfig.SingleDiff = ADC_SINGLE_ENDED;
  sConfig.OffsetNumber = ADC_OFFSET_NONE;
  sConfig.Offset = 0;
  sConfig.OffsetSignedSaturation = DISABLE;
  sConfig.OffsetSign = ADC3_OFFSET_SIGN_NEGATIVE;
  sConfig.OffsetSaturation = DISABLE;
  if (HAL_ADC_ConfigChannel(&hadc3, &sConfig) != HAL_OK)
  {
    Error_Handler();
  }

}

static void MX_CORDIC_Init(void)
{

  hcordic.Instance = CORDIC;
  if (HAL_CORDIC_Init(&hcordic) != HAL_OK)
  {
    Error_Handler();
  }

}

static void MX_DFSDM1_Init(void)
{

  hdfsdm1_filter0.Instance = DFSDM1_Filter0;
  hdfsdm1_filter0.Init.RegularParam.Trigger = DFSDM_FILTER_SW_TRIGGER;
  hdfsdm1_filter0.Init.RegularParam.FastMode = DISABLE;
  hdfsdm1_filter0.Init.RegularParam.DmaMode = DISABLE;
  hdfsdm1_filter0.Init.FilterParam.SincOrder = DFSDM_FILTER_SINC3_ORDER;
  hdfsdm1_filter0.Init.FilterParam.Oversampling = 32;
  hdfsdm1_filter0.Init.FilterParam.IntOversampling = 1;
  if (HAL_DFSDM_FilterInit(&hdfsdm1_filter0) != HAL_OK)
  {
    Error_Handler();
  }
  hdfsdm1_filter1.Instance = DFSDM1_Filter1;
  hdfsdm1_filter1.Init.RegularParam.Trigger = DFSDM_FILTER_SW_TRIGGER;
  hdfsdm1_filter1.Init.RegularParam.FastMode = DISABLE;
  hdfsdm1_filter1.Init.RegularParam.DmaMode = DISABLE;
  hdfsdm1_filter1.Init.FilterParam.SincOrder = DFSDM_FILTER_SINC3_ORDER;
  hdfsdm1_filter1.Init.FilterParam.Oversampling = 32;
  hdfsdm1_filter1.Init.FilterParam.IntOversampling = 1;
  if (HAL_DFSDM_FilterInit(&hdfsdm1_filter1) != HAL_OK)
  {
    Error_Handler();
  }
  hdfsdm1_filter2.Instance = DFSDM1_Filter2;
  hdfsdm1_filter2.Init.RegularParam.Trigger = DFSDM_FILTER_SW_TRIGGER;
  hdfsdm1_filter2.Init.RegularParam.FastMode = DISABLE;
  hdfsdm1_filter2.Init.RegularParam.DmaMode = DISABLE;
  hdfsdm1_filter2.Init.FilterParam.SincOrder = DFSDM_FILTER_SINC3_ORDER;
  hdfsdm1_filter2.Init.FilterParam.Oversampling = 32;
  hdfsdm1_filter2.Init.FilterParam.IntOversampling = 1;
  if (HAL_DFSDM_FilterInit(&hdfsdm1_filter2) != HAL_OK)
  {
    Error_Handler();
  }
  hdfsdm1_filter3.Instance = DFSDM1_Filter3;
  hdfsdm1_filter3.Init.RegularParam.Trigger = DFSDM_FILTER_SW_TRIGGER;
  hdfsdm1_filter3.Init.RegularParam.FastMode = DISABLE;
  hdfsdm1_filter3.Init.RegularParam.DmaMode = DISABLE;
  hdfsdm1_filter3.Init.FilterParam.SincOrder = DFSDM_FILTER_SINC3_ORDER;
  hdfsdm1_filter3.Init.FilterParam.Oversampling = 32;
  hdfsdm1_filter3.Init.FilterParam.IntOversampling = 1;
  if (HAL_DFSDM_FilterInit(&hdfsdm1_filter3) != HAL_OK)
  {
    Error_Handler();
  }
  hdfsdm1_channel1.Instance = DFSDM1_Channel1;
  hdfsdm1_channel1.Init.OutputClock.Activation = DISABLE;
  hdfsdm1_channel1.Init.OutputClock.Selection = DFSDM_CHANNEL_OUTPUT_CLOCK_SYSTEM;
  hdfsdm1_channel1.Init.OutputClock.Divider = 2;
  hdfsdm1_channel1.Init.Input.Multiplexer = DFSDM_CHANNEL_EXTERNAL_INPUTS;
  hdfsdm1_channel1.Init.Input.DataPacking = DFSDM_CHANNEL_STANDARD_MODE;
  hdfsdm1_channel1.Init.Input.Pins = DFSDM_CHANNEL_SAME_CHANNEL_PINS;
  hdfsdm1_channel1.Init.SerialInterface.Type = DFSDM_CHANNEL_SPI_RISING;
  hdfsdm1_channel1.Init.SerialInterface.SpiClock = DFSDM_CHANNEL_SPI_CLOCK_EXTERNAL;
  hdfsdm1_channel1.Init.Awd.FilterOrder = DFSDM_CHANNEL_FASTSINC_ORDER;
  hdfsdm1_channel1.Init.Awd.Oversampling = 1;
  hdfsdm1_channel1.Init.Offset = 0;
  hdfsdm1_channel1.Init.RightBitShift = 0x00;
  if (HAL_DFSDM_ChannelInit(&hdfsdm1_channel1) != HAL_OK)
  {
    Error_Handler();
  }
  hdfsdm1_channel2.Instance = DFSDM1_Channel2;
  hdfsdm1_channel2.Init.OutputClock.Activation = DISABLE;
  hdfsdm1_channel2.Init.OutputClock.Selection = DFSDM_CHANNEL_OUTPUT_CLOCK_SYSTEM;
  hdfsdm1_channel2.Init.OutputClock.Divider = 2;
  hdfsdm1_channel2.Init.Input.Multiplexer = DFSDM_CHANNEL_EXTERNAL_INPUTS;
  hdfsdm1_channel2.Init.Input.DataPacking = DFSDM_CHANNEL_STANDARD_MODE;
  hdfsdm1_channel2.Init.Input.Pins = DFSDM_CHANNEL_SAME_CHANNEL_PINS;
  hdfsdm1_channel2.Init.SerialInterface.Type = DFSDM_CHANNEL_SPI_RISING;
  hdfsdm1_channel2.Init.SerialInterface.SpiClock = DFSDM_CHANNEL_SPI_CLOCK_EXTERNAL;
  hdfsdm1_channel2.Init.Awd.FilterOrder = DFSDM_CHANNEL_FASTSINC_ORDER;
  hdfsdm1_channel2.Init.Awd.Oversampling = 1;
  hdfsdm1_channel2.Init.Offset = 0;
  hdfsdm1_channel2.Init.RightBitShift = 0x00;
  if (HAL_DFSDM_ChannelInit(&hdfsdm1_channel2) != HAL_OK)
  {
    Error_Handler();
  }
  hdfsdm1_channel4.Instance = DFSDM1_Channel4;
  hdfsdm1_channel4.Init.OutputClock.Activation = DISABLE;
  hdfsdm1_channel4.Init.OutputClock.Selection = DFSDM_CHANNEL_OUTPUT_CLOCK_SYSTEM;
  hdfsdm1_channel4.Init.OutputClock.Divider = 2;
  hdfsdm1_channel4.Init.Input.Multiplexer = DFSDM_CHANNEL_EXTERNAL_INPUTS;
  hdfsdm1_channel4.Init.Input.DataPacking = DFSDM_CHANNEL_STANDARD_MODE;
  hdfsdm1_channel4.Init.Input.Pins = DFSDM_CHANNEL_SAME_CHANNEL_PINS;
  hdfsdm1_channel4.Init.SerialInterface.Type = DFSDM_CHANNEL_SPI_RISING;
  hdfsdm1_channel4.Init.SerialInterface.SpiClock = DFSDM_CHANNEL_SPI_CLOCK_EXTERNAL;
  hdfsdm1_channel4.Init.Awd.FilterOrder = DFSDM_CHANNEL_FASTSINC_ORDER;
  hdfsdm1_channel4.Init.Awd.Oversampling = 1;
  hdfsdm1_channel4.Init.Offset = 0;
  hdfsdm1_channel4.Init.RightBitShift = 0x00;
  if (HAL_DFSDM_ChannelInit(&hdfsdm1_channel4) != HAL_OK)
  {
    Error_Handler();
  }
  hdfsdm1_channel5.Instance = DFSDM1_Channel5;
  hdfsdm1_channel5.Init.OutputClock.Activation = DISABLE;
  hdfsdm1_channel5.Init.OutputClock.Selection = DFSDM_CHANNEL_OUTPUT_CLOCK_SYSTEM;
  hdfsdm1_channel5.Init.OutputClock.Divider = 2;
  hdfsdm1_channel5.Init.Input.Multiplexer = DFSDM_CHANNEL_EXTERNAL_INPUTS;
  hdfsdm1_channel5.Init.Input.DataPacking = DFSDM_CHANNEL_STANDARD_MODE;
  hdfsdm1_channel5.Init.Input.Pins = DFSDM_CHANNEL_SAME_CHANNEL_PINS;
  hdfsdm1_channel5.Init.SerialInterface.Type = DFSDM_CHANNEL_SPI_RISING;
  hdfsdm1_channel5.Init.SerialInterface.SpiClock = DFSDM_CHANNEL_SPI_CLOCK_EXTERNAL;
  hdfsdm1_channel5.Init.Awd.FilterOrder = DFSDM_CHANNEL_FASTSINC_ORDER;
  hdfsdm1_channel5.Init.Awd.Oversampling = 1;
  hdfsdm1_channel5.Init.Offset = 0;
  hdfsdm1_channel5.Init.RightBitShift = 0x00;
  if (HAL_DFSDM_ChannelInit(&hdfsdm1_channel5) != HAL_OK)
  {
    Error_Handler();
  }
  if (HAL_DFSDM_FilterConfigRegChannel(&hdfsdm1_filter0, DFSDM_CHANNEL_1, DFSDM_CONTINUOUS_CONV_ON) != HAL_OK)
  {
    Error_Handler();
  }
  if (HAL_DFSDM_FilterConfigRegChannel(&hdfsdm1_filter1, DFSDM_CHANNEL_2, DFSDM_CONTINUOUS_CONV_ON) != HAL_OK)
  {
    Error_Handler();
  }
  if (HAL_DFSDM_FilterConfigRegChannel(&hdfsdm1_filter2, DFSDM_CHANNEL_4, DFSDM_CONTINUOUS_CONV_ON) != HAL_OK)
  {
    Error_Handler();
  }
  if (HAL_DFSDM_FilterConfigRegChannel(&hdfsdm1_filter3, DFSDM_CHANNEL_5, DFSDM_CONTINUOUS_CONV_ON) != HAL_OK)
  {
    Error_Handler();
  }

}

static void MX_FDCAN1_Init(void)
{

  hfdcan1.Instance = FDCAN1;
  hfdcan1.Init.FrameFormat = FDCAN_FRAME_CLASSIC;
  hfdcan1.Init.Mode = FDCAN_MODE_NORMAL;
  hfdcan1.Init.AutoRetransmission = DISABLE;
  hfdcan1.Init.TransmitPause = DISABLE;
  hfdcan1.Init.ProtocolException = DISABLE;
  hfdcan1.Init.NominalPrescaler = 1;
  hfdcan1.Init.NominalSyncJumpWidth = 1;
  hfdcan1.Init.NominalTimeSeg1 = 2;
  hfdcan1.Init.NominalTimeSeg2 = 2;
  hfdcan1.Init.DataPrescaler = 1;
  hfdcan1.Init.DataSyncJumpWidth = 1;
  hfdcan1.Init.DataTimeSeg1 = 1;
  hfdcan1.Init.DataTimeSeg2 = 1;
  hfdcan1.Init.MessageRAMOffset = 0;
  hfdcan1.Init.StdFiltersNbr = 0;
  hfdcan1.Init.ExtFiltersNbr = 0;
  hfdcan1.Init.RxFifo0ElmtsNbr = 0;
  hfdcan1.Init.RxFifo0ElmtSize = FDCAN_DATA_BYTES_8;
  hfdcan1.Init.RxFifo1ElmtsNbr = 0;
  hfdcan1.Init.RxFifo1ElmtSize = FDCAN_DATA_BYTES_8;
  hfdcan1.Init.RxBuffersNbr = 0;
  hfdcan1.Init.RxBufferSize = FDCAN_DATA_BYTES_8;
  hfdcan1.Init.TxEventsNbr = 0;
  hfdcan1.Init.TxBuffersNbr = 0;
  hfdcan1.Init.TxFifoQueueElmtsNbr = 0;
  hfdcan1.Init.TxFifoQueueMode = FDCAN_TX_FIFO_OPERATION;
  hfdcan1.Init.TxElmtSize = FDCAN_DATA_BYTES_8;
  if (HAL_FDCAN_Init(&hfdcan1) != HAL_OK)
  {
    Error_Handler();
  }

}

static void MX_FMAC_Init(void)
{

  hfmac.Instance = FMAC;
  if (HAL_FMAC_Init(&hfmac) != HAL_OK)
  {
    Error_Handler();
  }

}

static void MX_SPI2_Init(void)
{

  /* SPI2 parameter configuration*/
  hspi2.Instance = SPI2;
  hspi2.Init.Mode = SPI_MODE_MASTER;
  hspi2.Init.Direction = SPI_DIRECTION_2LINES;
  hspi2.Init.DataSize = SPI_DATASIZE_16BIT;
  hspi2.Init.CLKPolarity = SPI_POLARITY_LOW;
  hspi2.Init.CLKPhase = SPI_PHASE_2EDGE;
  hspi2.Init.NSS = SPI_NSS_HARD_OUTPUT;
  hspi2.Init.BaudRatePrescaler = SPI_BAUDRATEPRESCALER_64;
  hspi2.Init.FirstBit = SPI_FIRSTBIT_MSB;
  hspi2.Init.TIMode = SPI_TIMODE_DISABLE;
  hspi2.Init.CRCCalculation = SPI_CRCCALCULATION_DISABLE;
  hspi2.Init.CRCPolynomial = 0x0;
  hspi2.Init.NSSPMode = SPI_NSS_PULSE_DISABLE;
  hspi2.Init.NSSPolarity = SPI_NSS_POLARITY_LOW;
  hspi2.Init.FifoThreshold = SPI_FIFO_THRESHOLD_01DATA;
  hspi2.Init.TxCRCInitializationPattern = SPI_CRC_INITIALIZATION_ALL_ZERO_PATTERN;
  hspi2.Init.RxCRCInitializationPattern = SPI_CRC_INITIALIZATION_ALL_ZERO_PATTERN;
  hspi2.Init.MasterSSIdleness = SPI_MASTER_SS_IDLENESS_00CYCLE;
  hspi2.Init.MasterInterDataIdleness = SPI_MASTER_INTERDATA_IDLENESS_00CYCLE;
  hspi2.Init.MasterReceiverAutoSusp = SPI_MASTER_RX_AUTOSUSP_DISABLE;
  hspi2.Init.MasterKeepIOState = SPI_MASTER_KEEP_IO_STATE_ENABLE;
  hspi2.Init.IOSwap = SPI_IO_SWAP_DISABLE;
  if (HAL_SPI_Init(&hspi2) != HAL_OK)
  {
    Error_Handler();
  }

}

static void MX_SPI3_Init(void)
{

  /* SPI3 parameter configuration*/
  hspi3.Instance = SPI3;
  hspi3.Init.Mode = SPI_MODE_MASTER;
  hspi3.Init.Direction = SPI_DIRECTION_2LINES;
  hspi3.Init.DataSize = SPI_DATASIZE_16BIT;
  hspi3.Init.CLKPolarity = SPI_POLARITY_LOW;
  hspi3.Init.CLKPhase = SPI_PHASE_2EDGE;
  hspi3.Init.NSS = SPI_NSS_HARD_OUTPUT;
  hspi3.Init.BaudRatePrescaler = SPI_BAUDRATEPRESCALER_64;
  hspi3.Init.FirstBit = SPI_FIRSTBIT_MSB;
  hspi3.Init.TIMode = SPI_TIMODE_DISABLE;
  hspi3.Init.CRCCalculation = SPI_CRCCALCULATION_DISABLE;
  hspi3.Init.CRCPolynomial = 0x0;
  hspi3.Init.NSSPMode = SPI_NSS_PULSE_DISABLE;
  hspi3.Init.NSSPolarity = SPI_NSS_POLARITY_LOW;
  hspi3.Init.FifoThreshold = SPI_FIFO_THRESHOLD_01DATA;
  hspi3.Init.TxCRCInitializationPattern = SPI_CRC_INITIALIZATION_ALL_ZERO_PATTERN;
  hspi3.Init.RxCRCInitializationPattern = SPI_CRC_INITIALIZATION_ALL_ZERO_PATTERN;
  hspi3.Init.MasterSSIdleness = SPI_MASTER_SS_IDLENESS_00CYCLE;
  hspi3.Init.MasterInterDataIdleness = SPI_MASTER_INTERDATA_IDLENESS_00CYCLE;
  hspi3.Init.MasterReceiverAutoSusp = SPI_MASTER_RX_AUTOSUSP_DISABLE;
  hspi3.Init.MasterKeepIOState = SPI_MASTER_KEEP_IO_STATE_ENABLE;
  hspi3.Init.IOSwap = SPI_IO_SWAP_DISABLE;
  if (HAL_SPI_Init(&hspi3) != HAL_OK)
  {
    Error_Handler();
  }

}

static void MX_SPI4_Init(void)
{

  /* SPI4 parameter configuration*/
  hspi4.Instance = SPI4;
  hspi4.Init.Mode = SPI_MODE_MASTER;
  hspi4.Init.Direction = SPI_DIRECTION_2LINES;
  hspi4.Init.DataSize = SPI_DATASIZE_16BIT;
  hspi4.Init.CLKPolarity = SPI_POLARITY_HIGH;
  hspi4.Init.CLKPhase = SPI_PHASE_2EDGE;
  hspi4.Init.NSS = SPI_NSS_HARD_OUTPUT;
  hspi4.Init.BaudRatePrescaler = SPI_BAUDRATEPRESCALER_4;
  hspi4.Init.FirstBit = SPI_FIRSTBIT_MSB;
  hspi4.Init.TIMode = SPI_TIMODE_DISABLE;
  hspi4.Init.CRCCalculation = SPI_CRCCALCULATION_DISABLE;
  hspi4.Init.CRCPolynomial = 0x0;
  hspi4.Init.NSSPMode = SPI_NSS_PULSE_DISABLE;
  hspi4.Init.NSSPolarity = SPI_NSS_POLARITY_HIGH;
  hspi4.Init.FifoThreshold = SPI_FIFO_THRESHOLD_01DATA;
  hspi4.Init.TxCRCInitializationPattern = SPI_CRC_INITIALIZATION_ALL_ZERO_PATTERN;
  hspi4.Init.RxCRCInitializationPattern = SPI_CRC_INITIALIZATION_ALL_ZERO_PATTERN;
  hspi4.Init.MasterSSIdleness = SPI_MASTER_SS_IDLENESS_00CYCLE;
  hspi4.Init.MasterInterDataIdleness = SPI_MASTER_INTERDATA_IDLENESS_00CYCLE;
  hspi4.Init.MasterReceiverAutoSusp = SPI_MASTER_RX_AUTOSUSP_DISABLE;
  hspi4.Init.MasterKeepIOState = SPI_MASTER_KEEP_IO_STATE_ENABLE;
  hspi4.Init.IOSwap = SPI_IO_SWAP_DISABLE;
  if (HAL_SPI_Init(&hspi4) != HAL_OK)
  {
    Error_Handler();
  }

}

static void MX_SPI6_Init(void)
{

  /* SPI6 parameter configuration*/
  hspi6.Instance = SPI6;
  hspi6.Init.Mode = SPI_MODE_MASTER;
  hspi6.Init.Direction = SPI_DIRECTION_2LINES;
  hspi6.Init.DataSize = SPI_DATASIZE_16BIT;
  hspi6.Init.CLKPolarity = SPI_POLARITY_HIGH;
  hspi6.Init.CLKPhase = SPI_PHASE_2EDGE;
  hspi6.Init.NSS = SPI_NSS_HARD_OUTPUT;
  hspi6.Init.BaudRatePrescaler = SPI_BAUDRATEPRESCALER_4;
  hspi6.Init.FirstBit = SPI_FIRSTBIT_MSB;
  hspi6.Init.TIMode = SPI_TIMODE_DISABLE;
  hspi6.Init.CRCCalculation = SPI_CRCCALCULATION_DISABLE;
  hspi6.Init.CRCPolynomial = 0x0;
  hspi6.Init.NSSPMode = SPI_NSS_PULSE_DISABLE;
  hspi6.Init.NSSPolarity = SPI_NSS_POLARITY_HIGH;
  hspi6.Init.FifoThreshold = SPI_FIFO_THRESHOLD_01DATA;
  hspi6.Init.TxCRCInitializationPattern = SPI_CRC_INITIALIZATION_ALL_ZERO_PATTERN;
  hspi6.Init.RxCRCInitializationPattern = SPI_CRC_INITIALIZATION_ALL_ZERO_PATTERN;
  hspi6.Init.MasterSSIdleness = SPI_MASTER_SS_IDLENESS_00CYCLE;
  hspi6.Init.MasterInterDataIdleness = SPI_MASTER_INTERDATA_IDLENESS_00CYCLE;
  hspi6.Init.MasterReceiverAutoSusp = SPI_MASTER_RX_AUTOSUSP_DISABLE;
  hspi6.Init.MasterKeepIOState = SPI_MASTER_KEEP_IO_STATE_DISABLE;
  hspi6.Init.IOSwap = SPI_IO_SWAP_DISABLE;
  if (HAL_SPI_Init(&hspi6) != HAL_OK)
  {
    Error_Handler();
  }

}

static void MX_TIM1_Init(void)
{

  TIM_ClockConfigTypeDef sClockSourceConfig = {0};
  TIM_MasterConfigTypeDef sMasterConfig = {0};
  TIM_OC_InitTypeDef sConfigOC = {0};
  TIM_BreakDeadTimeConfigTypeDef sBreakDeadTimeConfig = {0};

  htim1.Instance = TIM1;
  htim1.Init.Prescaler = 0;
  htim1.Init.CounterMode = TIM_COUNTERMODE_UP;
  htim1.Init.Period = 10000;
  htim1.Init.ClockDivision = TIM_CLOCKDIVISION_DIV1;
  htim1.Init.RepetitionCounter = 0;
  htim1.Init.AutoReloadPreload = TIM_AUTORELOAD_PRELOAD_DISABLE;
  if (HAL_TIM_Base_Init(&htim1) != HAL_OK)
  {
    Error_Handler();
  }
  sClockSourceConfig.ClockSource = TIM_CLOCKSOURCE_INTERNAL;
  if (HAL_TIM_ConfigClockSource(&htim1, &sClockSourceConfig) != HAL_OK)
  {
    Error_Handler();
  }
  if (HAL_TIM_PWM_Init(&htim1) != HAL_OK)
  {
    Error_Handler();
  }
  sMasterConfig.MasterOutputTrigger = TIM_TRGO_RESET;
  sMasterConfig.MasterOutputTrigger2 = TIM_TRGO2_RESET;
  sMasterConfig.MasterSlaveMode = TIM_MASTERSLAVEMODE_DISABLE;
  if (HAL_TIMEx_MasterConfigSynchronization(&htim1, &sMasterConfig) != HAL_OK)
  {
    Error_Handler();
  }
  sConfigOC.OCMode = TIM_OCMODE_PWM1;
  sConfigOC.Pulse = 0;
  sConfigOC.OCPolarity = TIM_OCPOLARITY_HIGH;
  sConfigOC.OCNPolarity = TIM_OCNPOLARITY_HIGH;
  sConfigOC.OCFastMode = TIM_OCFAST_DISABLE;
  sConfigOC.OCIdleState = TIM_OCIDLESTATE_RESET;
  sConfigOC.OCNIdleState = TIM_OCNIDLESTATE_RESET;
  if (HAL_TIM_PWM_ConfigChannel(&htim1, &sConfigOC, TIM_CHANNEL_1) != HAL_OK)
  {
    Error_Handler();
  }
  if (HAL_TIM_PWM_ConfigChannel(&htim1, &sConfigOC, TIM_CHANNEL_2) != HAL_OK)
  {
    Error_Handler();
  }
  if (HAL_TIM_PWM_ConfigChannel(&htim1, &sConfigOC, TIM_CHANNEL_3) != HAL_OK)
  {
    Error_Handler();
  }
  sBreakDeadTimeConfig.OffStateRunMode = TIM_OSSR_DISABLE;
  sBreakDeadTimeConfig.OffStateIDLEMode = TIM_OSSI_DISABLE;
  sBreakDeadTimeConfig.LockLevel = TIM_LOCKLEVEL_OFF;
  sBreakDeadTimeConfig.DeadTime = 0;
  sBreakDeadTimeConfig.BreakState = TIM_BREAK_DISABLE;
  sBreakDeadTimeConfig.BreakPolarity = TIM_BREAKPOLARITY_HIGH;
  sBreakDeadTimeConfig.BreakFilter = 0;
  sBreakDeadTimeConfig.Break2State = TIM_BREAK2_DISABLE;
  sBreakDeadTimeConfig.Break2Polarity = TIM_BREAK2POLARITY_HIGH;
  sBreakDeadTimeConfig.Break2Filter = 0;
  sBreakDeadTimeConfig.AutomaticOutput = TIM_AUTOMATICOUTPUT_DISABLE;
  if (HAL_TIMEx_ConfigBreakDeadTime(&htim1, &sBreakDeadTimeConfig) != HAL_OK)
  {
    Error_Handler();
  }
  HAL_TIM_MspPostInit(&htim1);

}

static void MX_TIM2_Init(void)
{

  TIM_ClockConfigTypeDef sClockSourceConfig = {0};
  TIM_MasterConfigTypeDef sMasterConfig = {0};

  htim2.Instance = TIM2;
  htim2.Init.Prescaler = 0;
  htim2.Init.CounterMode = TIM_COUNTERMODE_UP;
  htim2.Init.Period = 655350;
  htim2.Init.ClockDivision = TIM_CLOCKDIVISION_DIV1;
  htim2.Init.AutoReloadPreload = TIM_AUTORELOAD_PRELOAD_DISABLE;
  if (HAL_TIM_Base_Init(&htim2) != HAL_OK)
  {
    Error_Handler();
  }
  sClockSourceConfig.ClockSource = TIM_CLOCKSOURCE_INTERNAL;
  if (HAL_TIM_ConfigClockSource(&htim2, &sClockSourceConfig) != HAL_OK)
  {
    Error_Handler();
  }
  sMasterConfig.MasterOutputTrigger = TIM_TRGO_RESET;
  sMasterConfig.MasterSlaveMode = TIM_MASTERSLAVEMODE_DISABLE;
  if (HAL_TIMEx_MasterConfigSynchronization(&htim2, &sMasterConfig) != HAL_OK)
  {
    Error_Handler();
  }

}

static void MX_TIM4_Init(void)
{

  TIM_ClockConfigTypeDef sClockSourceConfig = {0};
  TIM_MasterConfigTypeDef sMasterConfig = {0};
  TIM_OC_InitTypeDef sConfigOC = {0};

  htim4.Instance = TIM4;
  htim4.Init.Prescaler = 27500;
  htim4.Init.CounterMode = TIM_COUNTERMODE_UP;
  htim4.Init.Period = 20000;
  htim4.Init.ClockDivision = TIM_CLOCKDIVISION_DIV1;
  htim4.Init.AutoReloadPreload = TIM_AUTORELOAD_PRELOAD_DISABLE;
  if (HAL_TIM_Base_Init(&htim4) != HAL_OK)
  {
    Error_Handler();
  }
  sClockSourceConfig.ClockSource = TIM_CLOCKSOURCE_INTERNAL;
  if (HAL_TIM_ConfigClockSource(&htim4, &sClockSourceConfig) != HAL_OK)
  {
    Error_Handler();
  }
  if (HAL_TIM_PWM_Init(&htim4) != HAL_OK)
  {
    Error_Handler();
  }
  sMasterConfig.MasterOutputTrigger = TIM_TRGO_RESET;
  sMasterConfig.MasterSlaveMode = TIM_MASTERSLAVEMODE_DISABLE;
  if (HAL_TIMEx_MasterConfigSynchronization(&htim4, &sMasterConfig) != HAL_OK)
  {
    Error_Handler();
  }
  sConfigOC.OCMode = TIM_OCMODE_PWM1;
  sConfigOC.Pulse = 0;
  sConfigOC.OCPolarity = TIM_OCPOLARITY_HIGH;
  sConfigOC.OCFastMode = TIM_OCFAST_DISABLE;
  if (HAL_TIM_PWM_ConfigChannel(&htim4, &sConfigOC, TIM_CHANNEL_1) != HAL_OK)
  {
    Error_Handler();
  }
  HAL_TIM_MspPostInit(&htim4);

}

static void MX_TIM8_Init(void)
{

  TIM_ClockConfigTypeDef sClockSourceConfig = {0};
  TIM_MasterConfigTypeDef sMasterConfig = {0};
  TIM_OC_InitTypeDef sConfigOC = {0};
  TIM_BreakDeadTimeConfigTypeDef sBreakDeadTimeConfig = {0};

  htim8.Instance = TIM8;
  htim8.Init.Prescaler = 0;
  htim8.Init.CounterMode = TIM_COUNTERMODE_UP;
  htim8.Init.Period = 65535;
  htim8.Init.ClockDivision = TIM_CLOCKDIVISION_DIV1;
  htim8.Init.RepetitionCounter = 0;
  htim8.Init.AutoReloadPreload = TIM_AUTORELOAD_PRELOAD_DISABLE;
  if (HAL_TIM_Base_Init(&htim8) != HAL_OK)
  {
    Error_Handler();
  }
  sClockSourceConfig.ClockSource = TIM_CLOCKSOURCE_INTERNAL;
  if (HAL_TIM_ConfigClockSource(&htim8, &sClockSourceConfig) != HAL_OK)
  {
    Error_Handler();
  }
  if (HAL_TIM_PWM_Init(&htim8) != HAL_OK)
  {
    Error_Handler();
  }
  if (HAL_TIM_OC_Init(&htim8) != HAL_OK)
  {
    Error_Handler();
  }
  sMasterConfig.MasterOutputTrigger = TIM_TRGO_RESET;
  sMasterConfig.MasterOutputTrigger2 = TIM_TRGO2_RESET;
  sMasterConfig.MasterSlaveMode = TIM_MASTERSLAVEMODE_DISABLE;
  if (HAL_TIMEx_MasterConfigSynchronization(&htim8, &sMasterConfig) != HAL_OK)
  {
    Error_Handler();
  }
  sConfigOC.OCMode = TIM_OCMODE_PWM1;
  sConfigOC.Pulse = 0;
  sConfigOC.OCPolarity = TIM_OCPOLARITY_HIGH;
  sConfigOC.OCNPolarity = TIM_OCNPOLARITY_HIGH;
  sConfigOC.OCFastMode = TIM_OCFAST_DISABLE;
  sConfigOC.OCIdleState = TIM_OCIDLESTATE_RESET;
  sConfigOC.OCNIdleState = TIM_OCNIDLESTATE_RESET;
  if (HAL_TIM_PWM_ConfigChannel(&htim8, &sConfigOC, TIM_CHANNEL_1) != HAL_OK)
  {
    Error_Handler();
  }
  if (HAL_TIM_PWM_ConfigChannel(&htim8, &sConfigOC, TIM_CHANNEL_2) != HAL_OK)
  {
    Error_Handler();
  }
  sConfigOC.OCMode = TIM_OCMODE_TIMING;
  if (HAL_TIM_OC_ConfigChannel(&htim8, &sConfigOC, TIM_CHANNEL_3) != HAL_OK)
  {
    Error_Handler();
  }
  sBreakDeadTimeConfig.OffStateRunMode = TIM_OSSR_DISABLE;
  sBreakDeadTimeConfig.OffStateIDLEMode = TIM_OSSI_DISABLE;
  sBreakDeadTimeConfig.LockLevel = TIM_LOCKLEVEL_OFF;
  sBreakDeadTimeConfig.DeadTime = 0;
  sBreakDeadTimeConfig.BreakState = TIM_BREAK_DISABLE;
  sBreakDeadTimeConfig.BreakPolarity = TIM_BREAKPOLARITY_HIGH;
  sBreakDeadTimeConfig.BreakFilter = 0;
  sBreakDeadTimeConfig.Break2State = TIM_BREAK2_DISABLE;
  sBreakDeadTimeConfig.Break2Polarity = TIM_BREAK2POLARITY_HIGH;
  sBreakDeadTimeConfig.Break2Filter = 0;
  sBreakDeadTimeConfig.AutomaticOutput = TIM_AUTOMATICOUTPUT_DISABLE;
  if (HAL_TIMEx_ConfigBreakDeadTime(&htim8, &sBreakDeadTimeConfig) != HAL_OK)
  {
    Error_Handler();
  }
  HAL_TIM_MspPostInit(&htim8);

}

static void MX_DMA_Init(void)
{

  /* DMA controller clock enable */
  __HAL_RCC_DMA1_CLK_ENABLE();

  /* DMA interrupt init */
  /* DMA1_Stream1_IRQn interrupt configuration */
  HAL_NVIC_SetPriority(DMA1_Stream1_IRQn, 0, 0);
  HAL_NVIC_EnableIRQ(DMA1_Stream1_IRQn);

}

static void MX_GPIO_Init(void)
{
  GPIO_InitTypeDef GPIO_InitStruct = {0};

  /* GPIO Ports Clock Enable */
  __HAL_RCC_GPIOE_CLK_ENABLE();
  __HAL_RCC_GPIOH_CLK_ENABLE();
  __HAL_RCC_GPIOC_CLK_ENABLE();
  __HAL_RCC_GPIOA_CLK_ENABLE();
  __HAL_RCC_GPIOB_CLK_ENABLE();
  __HAL_RCC_GPIOD_CLK_ENABLE();

  /*Configure GPIO pin Output Level */
  HAL_GPIO_WritePin(GPIOA, FAULT_LED_Pin|BRD_EN_Pin, GPIO_PIN_RESET);

  /*Configure GPIO pin Output Level */
  HAL_GPIO_WritePin(GPIOD, DRV1_EN_Pin|INV2_EN_Pin|DRV2_EN_Pin, GPIO_PIN_RESET);

  /*Configure GPIO pin Output Level */
  HAL_GPIO_WritePin(INV1_EN_GPIO_Port, INV1_EN_Pin, GPIO_PIN_RESET);

  /*Configure GPIO pins : FAULT_LED_Pin BRD_EN_Pin */
  GPIO_InitStruct.Pin = FAULT_LED_Pin|BRD_EN_Pin;
  GPIO_InitStruct.Mode = GPIO_MODE_OUTPUT_PP;
  GPIO_InitStruct.Pull = GPIO_NOPULL;
  GPIO_InitStruct.Speed = GPIO_SPEED_FREQ_LOW;
  HAL_GPIO_Init(GPIOA, &GPIO_InitStruct);

  /*Configure GPIO pins : FAULT1_Pin nFault2_Pin */
  GPIO_InitStruct.Pin = FAULT1_Pin|nFault2_Pin;
  GPIO_InitStruct.Mode = GPIO_MODE_INPUT;
  GPIO_InitStruct.Pull = GPIO_NOPULL;
  HAL_GPIO_Init(GPIOD, &GPIO_InitStruct);

  /*Configure GPIO pins : DRV1_EN_Pin INV2_EN_Pin DRV2_EN_Pin */
  GPIO_InitStruct.Pin = DRV1_EN_Pin|INV2_EN_Pin|DRV2_EN_Pin;
  GPIO_InitStruct.Mode = GPIO_MODE_OUTPUT_PP;
  GPIO_InitStruct.Pull = GPIO_NOPULL;
  GPIO_InitStruct.Speed = GPIO_SPEED_FREQ_LOW;
  HAL_GPIO_Init(GPIOD, &GPIO_InitStruct);

  /*Configure GPIO pin : INV1_EN_Pin */
  GPIO_InitStruct.Pin = INV1_EN_Pin;
  GPIO_InitStruct.Mode = GPIO_MODE_OUTPUT_PP;
  GPIO_InitStruct.Pull = GPIO_NOPULL;
  GPIO_InitStruct.Speed = GPIO_SPEED_FREQ_LOW;
  HAL_GPIO_Init(INV1_EN_GPIO_Port, &GPIO_InitStruct);

}

void Error_Handler(void)
{
  /* USER CODE BEGIN Error_Handler_Debug */
  /* User can add his own implementation to report the HAL error return state */
  __disable_irq();
  HAL_GPIO_WritePin(FAULT_LED_GPIO_Port, FAULT_LED_Pin, GPIO_PIN_RESET);
  while (1)
  {

  }
  /* USER CODE END Error_Handler_Debug */
}
